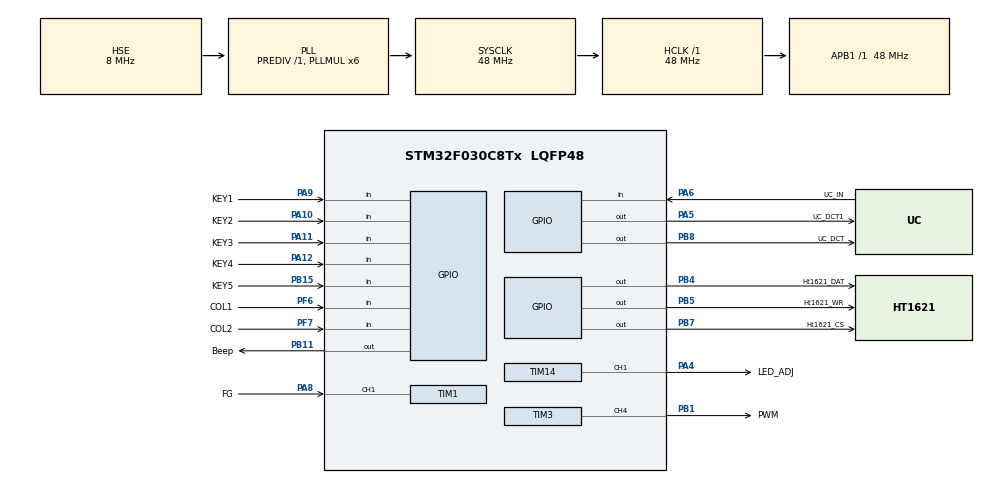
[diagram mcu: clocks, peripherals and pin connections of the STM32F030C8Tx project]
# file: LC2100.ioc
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Mcu.Family=STM32F0
Mcu.Name=STM32F030C8Tx
Mcu.Package=LQFP48
NVIC.TIM1_BRK_UP_TRG_COM_IRQn=true\:0\:0\:false\:false\:true\:true\:true\:true
NVIC.TIM1_CC_IRQn=true\:0\:0\:false\:false\:true\:true\:true\:true
NVIC.TIM3_IRQn=true\:0\:0\:false\:false\:true\:true\:true\:true
PA10.GPIO_Label=KEY2
PA10.Signal=GPIO_Input
PA11.GPIO_Label=KEY3
PA11.Signal=GPIO_Input
PA12.GPIO_Label=KEY4
PA12.Signal=GPIO_Input
PA13.Mode=Serial_Wire
PA13.Signal=SYS_SWDIO
PA14.Mode=Serial_Wire
PA14.Signal=SYS_SWCLK
PA4.GPIO_Label=LED_ADJ
PA4.Signal=S_TIM14_CH1
PA5.GPIO_Label=UC_DCT1
PA5.Signal=GPIO_Output
PA6.GPIO_Label=UC_IN
PA6.GPIO_PuPd=GPIO_PULLUP
PA6.Signal=GPIO_Input
PA8.GPIO_Label=FG
PA8.Signal=S_TIM1_CH1
PA9.GPIO_Label=KEY1
PA9.Signal=GPIO_Input
PB1.GPIO_Label=PWM
PB1.Signal=S_TIM3_CH4
PB11.GPIO_Label=Beep
PB11.GPIO_PuPd=GPIO_PULLDOWN
PB11.Signal=GPIO_Output
PB15.GPIO_Label=KEY5
PB15.Signal=GPIO_Input
PB4.GPIO_Label=Ht1621_DAT
PB4.GPIO_PuPd=GPIO_PULLUP
PB4.GPIO_Speed=GPIO_SPEED_FREQ_HIGH
PB4.PinState=GPIO_PIN_SET
PB4.Signal=GPIO_Output
PB5.GPIO_Label=Ht1621_WR
PB5.GPIO_PuPd=GPIO_PULLUP
PB5.GPIO_Speed=GPIO_SPEED_FREQ_HIGH
PB5.PinState=GPIO_PIN_SET
PB5.Signal=GPIO_Output
PB7.GPIO_FM7=__NULL
PB7.GPIO_Label=Ht1621_CS
PB7.GPIO_PuPd=GPIO_PULLUP
PB7.GPIO_Speed=GPIO_SPEED_FREQ_HIGH
PB7.PinState=GPIO_PIN_SET
PB7.Signal=GPIO_Output
PB8.GPIO_Label=UC_DCT
PB8.Signal=GPIO_Output
PF0-OSC_IN.Mode=HSE-External-Oscillator
PF0-OSC_IN.Signal=RCC_OSC_IN
PF1-OSC_OUT.Mode=HSE-External-Oscillator
PF1-OSC_OUT.Signal=RCC_OSC_OUT
PF6.GPIO_Label=COL1
PF6.GPIO_PuPd=GPIO_PULLUP
PF6.Signal=GPIO_Input
PF7.GPIO_Label=COL2
PF7.GPIO_PuPd=GPIO_PULLUP
PF7.Signal=GPIO_Input
ProjectManager.HeapSize=0x200
ProjectManager.StackSize=0x400
ProjectManager.TargetToolchain=MDK-ARM V5.32
RCC.AHBFreq_Value=48000000
RCC.APB1Freq_Value=48000000
RCC.APB1TimFreq_Value=48000000
RCC.HCLKFreq_Value=48000000
RCC.PLLMUL=RCC_PLL_MUL6
RCC.PLLSourceVirtual=RCC_PLLSOURCE_HSE
RCC.SYSCLKFreq_VALUE=48000000
RCC.SYSCLKSource=RCC_SYSCLKSOURCE_PLLCLK
SH.S_TIM14_CH1.0=TIM14_CH1,PWM Generation1 CH1
SH.S_TIM1_CH1.0=TIM1_CH1,Input_Capture1_from_TI1
SH.S_TIM3_CH4.0=TIM3_CH4,PWM Generation4 CH4
TIM1.Channel-Input_Capture1_from_TI1=TIM_CHANNEL_1
TIM1.Period=200
TIM1.Prescaler=12-1
TIM14.Channel=TIM_CHANNEL_1
TIM14.Period=200-1
TIM14.Prescaler=12-1
TIM3.Channel-PWM\ Generation4\ CH4=TIM_CHANNEL_4
TIM3.Period=400-1
TIM3.Prescaler=120-1
VP_TIM14_VS_ClockSourceINT.Mode=Enable_Timer
VP_TIM1_VS_ClockSourceINT.Mode=Internal
board=custom

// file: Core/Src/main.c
/* USER CODE BEGIN Header */
/**
  ******************************************************************************
  * @file           : main.c
  * @brief          : Main program body
  ******************************************************************************
  * @attention
  *
  * <h2><center>&copy; Copyright (c) 2022 STMicroelectronics.
  * All rights reserved.</center></h2>
  *
  * This software component is licensed by ST under BSD 3-Clause license,
  * the "License"; You may not use this file except in compliance with the
  * License. You may obtain a copy of the License at:
  *                        opensource.org/licenses/BSD-3-Clause
  *
  ******************************************************************************
  */
/* USER CODE END Header */
#include "main.h"
#include "tim.h"
#include "gpio.h"

void SystemClock_Config(void);

int main(void)
{

  /* MCU Configuration--------------------------------------------------------*/

  /* Reset of all peripherals, Initializes the Flash interface and the Systick. */
  HAL_Init();

  /* Configure the system clock */
  SystemClock_Config();

  /* Initialize all configured peripherals */
  MX_GPIO_Init();
  MX_TIM1_Init();
  MX_TIM3_Init();
  MX_TIM14_Init();
  /* USER CODE BEGIN 2 */
	System_Init();//ϵͳ������ʼ��
  /* USER CODE END 2 */

  /* Infinite loop */
  while (1)
  {

    /* USER CODE BEGIN 3 */
	  TIM1_Poll();//TIM1��ѵ״̬�л�
	  Show_Display();//��ʾ��Ļ����
  }
  /* USER CODE END 3 */
}

void SystemClock_Config(void)
{
  RCC_OscInitTypeDef RCC_OscInitStruct = {0};
  RCC_ClkInitTypeDef RCC_ClkInitStruct = {0};

  /** Initializes the RCC Oscillators according to the specified parameters
  * in the RCC_OscInitTypeDef structure.
  */
  RCC_OscInitStruct.OscillatorType = RCC_OSCILLATORTYPE_HSE;
  RCC_OscInitStruct.HSEState = RCC_HSE_ON;
  RCC_OscInitStruct.PLL.PLLState = RCC_PLL_ON;
  RCC_OscInitStruct.PLL.PLLSource = RCC_PLLSOURCE_HSE;
  RCC_OscInitStruct.PLL.PLLMUL = RCC_PLL_MUL6;
  RCC_OscInitStruct.PLL.PREDIV = RCC_PREDIV_DIV1;
  if (HAL_RCC_OscConfig(&RCC_OscInitStruct) != HAL_OK)
  {
    Error_Handler();
  }
  /** Initializes the CPU, AHB and APB buses clocks
  */
  RCC_ClkInitStruct.ClockType = RCC_CLOCKTYPE_HCLK|RCC_CLOCKTYPE_SYSCLK
                              |RCC_CLOCKTYPE_PCLK1;
  RCC_ClkInitStruct.SYSCLKSource = RCC_SYSCLKSOURCE_PLLCLK;
  RCC_ClkInitStruct.AHBCLKDivider = RCC_SYSCLK_DIV1;
  RCC_ClkInitStruct.APB1CLKDivider = RCC_HCLK_DIV1;

  if (HAL_RCC_ClockConfig(&RCC_ClkInitStruct, FLASH_LATENCY_1) != HAL_OK)
  {
    Error_Handler();
  }
}

void Error_Handler(void)
{
  __disable_irq();
  while (1)
  {
  }
}

/************************ (C) COPYRIGHT STMicroelectronics *****END OF FILE****/
